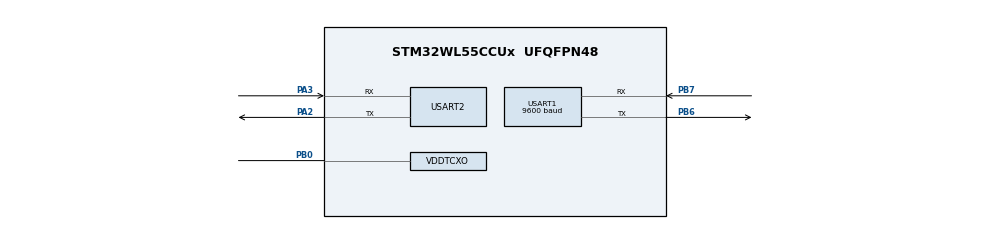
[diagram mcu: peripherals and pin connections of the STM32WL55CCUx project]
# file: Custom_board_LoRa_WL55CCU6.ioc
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ADC.ClockPrescaler=ADC_CLOCK_SYNC_PCLK_DIV4
ADC.NbrOfConversion=1
ADC.Overrun=ADC_OVR_DATA_OVERWRITTEN
ADC.SamplingTimeCommon1=ADC_SAMPLETIME_160CYCLES_5
ADC.SamplingTimeCommon2=ADC_SAMPLETIME_160CYCLES_5
ADC.SelectedChannel=ADC_CHANNEL_VREFINT
Dma.Request0=USART2_TX
Dma.USART2_TX.0.Channel_PRIV_NPRIV=DMA_CHANNEL_NPRIV_DISABLE
Dma.USART2_TX.0.Direction=DMA_MEMORY_TO_PERIPH
Dma.USART2_TX.0.EventEnable=DISABLE
Dma.USART2_TX.0.Instance=DMA1_Channel5
Dma.USART2_TX.0.MemDataAlignment=DMA_MDATAALIGN_BYTE
Dma.USART2_TX.0.MemInc=DMA_MINC_ENABLE
Dma.USART2_TX.0.Mode=DMA_NORMAL
Dma.USART2_TX.0.PeriphDataAlignment=DMA_PDATAALIGN_BYTE
Dma.USART2_TX.0.PeriphInc=DMA_PINC_DISABLE
Dma.USART2_TX.0.Polarity=HAL_DMAMUX_REQ_GEN_RISING
Dma.USART2_TX.0.Priority=DMA_PRIORITY_LOW
Dma.USART2_TX.0.RequestNumber=1
Dma.USART2_TX.0.SignalID=NONE
Dma.USART2_TX.0.SyncEnable=DISABLE
Dma.USART2_TX.0.SyncPolarity=HAL_DMAMUX_SYNC_NO_EVENT
Dma.USART2_TX.0.SyncRequestNumber=1
Dma.USART2_TX.0.SyncSignalID=NONE
LORAWAN.APP_TX_DUTYCYCLE=30000
LORAWAN.Activate_DEBUG_LINE=false
LORAWAN.Activate_RADIO_BOARD_INTERFACE=Bsp
LORAWAN.CONTEXT_MANAGEMENT_ENABLED=true
LORAWAN.LORAMAC_SPECIFICATION_VERSION=0x01000300
LORAWAN.LORAWAN_APP_S_KEY=8F,53,7D,7D,6A,75,DD,6D,67,F9,01,DA,57,A6,09,50
LORAWAN.LORAWAN_DATA_DISTRIB_MGT=false
LORAWAN.LORAWAN_DEFAULT_ACTIVATION_TYPE=ACTIVATION_TYPE_ABP
LORAWAN.LORAWAN_DEVICE_ADDRESS=26,0B,B1,94
LORAWAN.LORAWAN_NWK_S_KEY=EA,4B,62,BD,32,D5,BF,3E,3D,18,03,FF,72,42,B8,C2
LORAWAN.LOW_POWER_DISABLE=true
LORAWAN.REGION_US915=false
LORAWAN.SUBGHZ_APPLICATION=LORA_END_NODE
LORAWAN.VERBOSE_LEVEL=VLEVEL_M
LoRaWAN.BSP.number=3
LoRaWAN0.BSP.STBoard=false
LoRaWAN0.BSP.api=Unknown
LoRaWAN0.BSP.condition=\!SEM_LORA_USER_APPLICATION | SEM_LORA_USE_ADC
LoRaWAN0.BSP.instance=ADC
LoRaWAN0.BSP.ip=ADC
LoRaWAN0.BSP.mode=Vrefint Channel
LoRaWAN0.BSP.name=ADC
LoRaWAN0.BSP.solution=ADC
LoRaWAN1.BSP.STBoard=false
LoRaWAN1.BSP.api=Unknown
LoRaWAN1.BSP.condition=\!SEM_LORA_USER_APPLICATION | SEM_LORA_USE_RTC
LoRaWAN1.BSP.instance=RTC
LoRaWAN1.BSP.ip=RTC
LoRaWAN1.BSP.mode=RTC Enabled
LoRaWAN1.BSP.name=RTC
LoRaWAN1.BSP.solution=RTC
LoRaWAN2.BSP.STBoard=false
LoRaWAN2.BSP.api=Unknown
LoRaWAN2.BSP.condition=SEM_LORA_END_NODE  | SEM_LORA_USE_UART
LoRaWAN2.BSP.instance=USART2
LoRaWAN2.BSP.ip=(LPU|US)ART
LoRaWAN2.BSP.mode=Asynchronous
LoRaWAN2.BSP.name=USART
LoRaWAN2.BSP.solution=USART2
Mcu.Family=STM32WL
Mcu.Name=STM32WL55CCUx
Mcu.Package=UFQFPN48
Mcu.UserConstants=RTC_N_PREDIV_S,10;RTC_PREDIV_S,((1<<RTC_N_PREDIV_S)-1);RTC_PREDIV_A,((1<<(15-RTC_N_PREDIV_S))-1)
NVIC.DMA1_Channel5_IRQn=true\:2\:0\:true\:false\:true\:false\:true\:true
NVIC.PriorityGroup=NVIC_PRIORITYGROUP_4
NVIC.RTC_Alarm_IRQn=true\:0\:0\:false\:false\:true\:true\:true\:true
NVIC.SUBGHZ_Radio_IRQn=true\:0\:0\:false\:false\:true\:true\:true\:true
NVIC.TAMP_STAMP_LSECSS_SSRU_IRQn=true\:0\:0\:false\:false\:true\:true\:true\:true
NVIC.TimeBase=None
NVIC.USART1_IRQn=true\:2\:0\:true\:false\:true\:true\:true\:true
NVIC.USART2_IRQn=true\:2\:0\:true\:false\:true\:true\:true\:true
OSC_IN.Mode=HSE-TCXO
OSC_IN.Signal=RCC_OSC_IN
PA2.GPIO_Speed=GPIO_SPEED_FREQ_VERY_HIGH
PA2.Mode=Asynchronous
PA2.Signal=USART2_TX
PA3.GPIO_PuPd=GPIO_PULLUP
PA3.GPIO_Speed=GPIO_SPEED_FREQ_VERY_HIGH
PA3.Mode=Asynchronous
PA3.Signal=USART2_RX
PB0-VDD_TCXO.Mode=HSE-TCXO
PB0-VDD_TCXO.Signal=VDDTCXO
PB6.GPIO_ModeDefaultPP=GPIO_MODE_AF_PP
PB6.GPIO_PuPd=GPIO_NOPULL
PB6.GPIO_Speed=GPIO_SPEED_FREQ_VERY_HIGH
PB6.Mode=Asynchronous
PB6.Signal=USART1_TX
PB7.GPIO_ModeDefaultPP=GPIO_MODE_AF_PP
PB7.GPIO_PuPd=GPIO_PULLUP
PB7.GPIO_Speed=GPIO_SPEED_FREQ_VERY_HIGH
PB7.Mode=Asynchronous
PB7.Signal=USART1_RX
PC14-OSC32_IN.Mode=LSE-External-Oscillator
PC14-OSC32_IN.Signal=RCC_OSC32_IN
PC15-OSC32_OUT.Mode=LSE-External-Oscillator
PC15-OSC32_OUT.Signal=RCC_OSC32_OUT
ProjectManager.HeapSize=0x200
ProjectManager.StackSize=0x400
ProjectManager.TargetToolchain=STM32CubeIDE
RCC.AHBFreq_Value=16000000
RCC.APB1Freq_Value=16000000
RCC.APB1TimFreq_Value=16000000
RCC.APB2Freq_Value=16000000
RCC.APB2TimFreq_Value=16000000
RCC.APB3Freq_Value=16000000
RCC.CortexFreq_Value=16000000
RCC.FLatency=FLASH_LATENCY_2
RCC.HCLKFreq_Value=16000000
RCC.HSEPRES=2
RCC.HSE_VALUE=32000000
RCC.HSI_VALUE=16000000
RCC.LSE_VALUE=32768
RCC.MSIClockRange=RCC_MSIRANGE_8
RCC.PLLR=RCC_PLLR_DIV8
RCC.PLLSourceVirtual=RCC_PLLSOURCE_HSE
RCC.PWR_Regulator_Voltage_Scale=PWR_REGULATOR_VOLTAGE_SCALE1
RCC.RTCClockSelection=RCC_RTCCLKSOURCE_LSE
RCC.SYSCLKFreq_VALUE=16000000
RCC.VCOOutputFreq_Value=128000000
RTC.Alarm-Alarm\ A=RTC_ALARM_A
RTC.AsynchPrediv=RTC_PREDIV_A
RTC.BinMode=RTC_BINARY_ONLY
RTC.BinaryAutoClr_A-Alarm\ A=RTC_ALARMSUBSECONDBIN_AUTOCLR_NO
SUBGHZ.BaudratePrescaler=SUBGHZSPI_BAUDRATEPRESCALER_4
USART1.BaudRate=9600
USART1.VirtualMode-Asynchronous=VM_ASYNC
USART2.VirtualMode-Asynchronous=VM_ASYNC
VP_ADC_Vref_Input.Mode=IN-Vrefint
VP_ADV_TRACE_VS_ADV_TRACE.Mode=ADV_TRACE_Enabled
VP_LORAWAN_VS_LoRaWAN.Mode=LoRaWAN_Enabled
VP_MISC_VS_MISC.Mode=MISC_Enabled
VP_RTC_VS_RTC_Activate.Mode=RTC_Enabled
VP_RTC_VS_RTC_Alarm_A_Intern.Mode=Alarm A
VP_RTC_VS_RTC_Calendar.Mode=RTC_Calendar
VP_SEQUENCER_M4_VS_SEQUENCER.Mode=SEQUENCER_Enabled
VP_SUBGHZ_VS_SUBGHZ.Mode=SUBGHZ_Activate
VP_SYS_VS_None.Mode=None
VP_TIMER_VS_TIMER.Mode=TIMER_Enabled
VP_TINY_LPM_VS_TINY_LPM.Mode=TINY_LPM_Enabled
board=custom

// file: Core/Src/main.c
/* USER CODE BEGIN Header */
/**
  ******************************************************************************
  * @file           : main.c
  * @brief          : Main program body
  ******************************************************************************
  * @attention
  *
  * Copyright (c) 2025 STMicroelectronics.
  * All rights reserved.
  *
  * This software is licensed under terms that can be found in the LICENSE file
  * in the root directory of this software component.
  * If no LICENSE file comes with this software, it is provided AS-IS.
  *
  ******************************************************************************
  */
/* USER CODE END Header */
#include "main.h"
#include "adc.h"
#include "dma.h"
#include "app_lorawan.h"
#include "rtc.h"
#include "usart.h"
#include "gpio.h"

/* USER CODE BEGIN PV */
uint8_t rx_buff[1];
/* USER CODE END PV */

void SystemClock_Config(void);

int main(void)
{

  /* MCU Configuration--------------------------------------------------------*/

  /* Reset of all peripherals, Initializes the Flash interface and the Systick. */
  HAL_Init();

  /* Configure the system clock */
  SystemClock_Config();

  /* Initialize all configured peripherals */
  MX_GPIO_Init();
  MX_DMA_Init();
  MX_ADC_Init();
  MX_RTC_Init();
  MX_LoRaWAN_Init();
  MX_USART1_UART_Init();
  MX_USART2_UART_Init();
  /* USER CODE BEGIN 2 */
  //HAL_UART_Transmit(&huart1, (uint8_t *)"K 0\r\n", 5, 0xFFFF);
  //HAL_UART_Transmit(&huart2, (uint8_t *)"prova\r\n", 7, 100);

  HAL_UART_Receive_IT(&huart1, rx_buff, 1); // do not remove it!
  HAL_UART_Receive_IT(&huart2, rx_buff, 1);
  /* USER CODE END 2 */

  /* Infinite loop */
  while (1)
  {
    MX_LoRaWAN_Process();

  }
}

void SystemClock_Config(void)
{
  RCC_OscInitTypeDef RCC_OscInitStruct = {0};
  RCC_ClkInitTypeDef RCC_ClkInitStruct = {0};

  /** Configure LSE Drive Capability
  */
  HAL_PWR_EnableBkUpAccess();
  __HAL_RCC_LSEDRIVE_CONFIG(RCC_LSEDRIVE_LOW);

  /** Configure the main internal regulator output voltage
  */
  __HAL_PWR_VOLTAGESCALING_CONFIG(PWR_REGULATOR_VOLTAGE_SCALE1);

  /** Initializes the CPU, AHB and APB buses clocks
  */
  RCC_OscInitStruct.OscillatorType = RCC_OSCILLATORTYPE_LSE|RCC_OSCILLATORTYPE_MSI;
  RCC_OscInitStruct.LSEState = RCC_LSE_ON;
  RCC_OscInitStruct.MSIState = RCC_MSI_ON;
  RCC_OscInitStruct.MSICalibrationValue = RCC_MSICALIBRATION_DEFAULT;
  RCC_OscInitStruct.MSIClockRange = RCC_MSIRANGE_8;
  RCC_OscInitStruct.PLL.PLLState = RCC_PLL_NONE;
  if (HAL_RCC_OscConfig(&RCC_OscInitStruct) != HAL_OK)
  {
    Error_Handler();
  }

  /** Configure the SYSCLKSource, HCLK, PCLK1 and PCLK2 clocks dividers
  */
  RCC_ClkInitStruct.ClockType = RCC_CLOCKTYPE_HCLK3|RCC_CLOCKTYPE_HCLK
                              |RCC_CLOCKTYPE_SYSCLK|RCC_CLOCKTYPE_PCLK1
                              |RCC_CLOCKTYPE_PCLK2;
  RCC_ClkInitStruct.SYSCLKSource = RCC_SYSCLKSOURCE_MSI;
  RCC_ClkInitStruct.AHBCLKDivider = RCC_SYSCLK_DIV1;
  RCC_ClkInitStruct.APB1CLKDivider = RCC_HCLK_DIV1;
  RCC_ClkInitStruct.APB2CLKDivider = RCC_HCLK_DIV1;
  RCC_ClkInitStruct.AHBCLK3Divider = RCC_SYSCLK_DIV1;

  if (HAL_RCC_ClockConfig(&RCC_ClkInitStruct, FLASH_LATENCY_2) != HAL_OK)
  {
    Error_Handler();
  }
}

void Error_Handler(void)
{
  __disable_irq();
  while (1)
  {
  }
}
